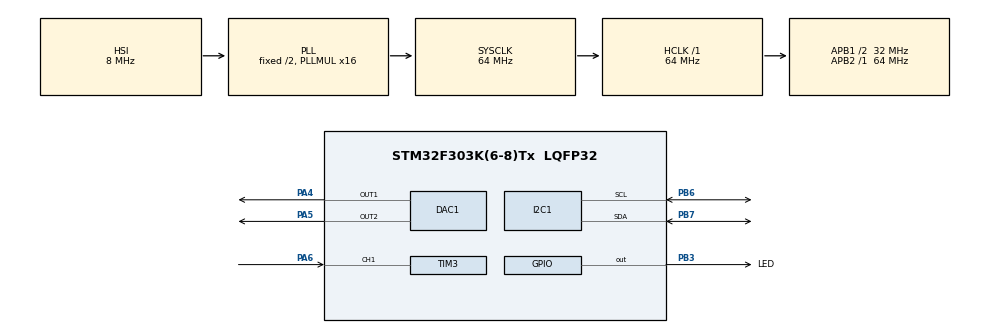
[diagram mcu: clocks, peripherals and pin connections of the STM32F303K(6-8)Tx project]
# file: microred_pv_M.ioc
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I2C1.I2C_Fall_Time=0
I2C1.I2C_Rise_Time=0
I2C1.OwnAddress=16
Mcu.Family=STM32F3
Mcu.Name=STM32F303K(6-8)Tx
Mcu.Package=LQFP32
NVIC.I2C1_ER_IRQn=true\:2\:0\:true\:false\:true\:true\:true\:true
NVIC.I2C1_EV_IRQn=true\:2\:0\:true\:false\:true\:true\:true\:true
NVIC.PriorityGroup=NVIC_PRIORITYGROUP_4
NVIC.TIM6_DAC1_IRQn=true\:1\:0\:true\:false\:true\:true\:true\:true
PA13.Mode=Serial_Wire
PA13.Signal=SYS_JTMS-SWDIO
PA14.Mode=Serial_Wire
PA14.Signal=SYS_JTCK-SWCLK
PA4.Signal=COMP_DAC11_group
PA5.Signal=COMP_DAC12_group
PA6.Signal=S_TIM3_CH1
PB3.GPIO_Label=LED
PB3.Signal=GPIO_Output
PB6.Mode=I2C
PB6.Signal=I2C1_SCL
PB7.Mode=I2C
PB7.Signal=I2C1_SDA
ProjectManager.HeapSize=0x200
ProjectManager.StackSize=0x400
ProjectManager.TargetToolchain=CMake
RCC.AHBFreq_Value=64000000
RCC.APB1CLKDivider=RCC_HCLK_DIV2
RCC.APB1Freq_Value=32000000
RCC.APB1TimFreq_Value=64000000
RCC.APB2Freq_Value=64000000
RCC.APB2TimFreq_Value=64000000
RCC.CortexFreq_Value=64000000
RCC.HCLKFreq_Value=64000000
RCC.HSE_VALUE=8000000
RCC.HSI_VALUE=8000000
RCC.PLLMUL=RCC_PLL_MUL16
RCC.SYSCLKFreq_VALUE=64000000
RCC.SYSCLKSourceVirtual=RCC_SYSCLKSOURCE_PLLCLK
SH.COMP_DAC11_group.0=DAC1_OUT1,DAC_OUT1
SH.COMP_DAC12_group.0=DAC1_OUT2,DAC_OUT2
SH.S_TIM3_CH1.0=TIM3_CH1,PWM_Input_1
TIM6.Period=99
TIM6.Prescaler=63
VP_TIM3_VS_ClockSourceINT.Mode=Internal
VP_TIM6_VS_ClockSourceINT.Mode=Enable_Timer
board=custom

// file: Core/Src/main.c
/* USER CODE BEGIN Header */
/**
  ******************************************************************************
  * @file           : main.c
  * @brief          : Main program body
  ******************************************************************************
  * @attention
  *
  * Copyright (c) 2026 STMicroelectronics.
  * All rights reserved.
  *
  * This software is licensed under terms that can be found in the LICENSE file
  * in the root directory of this software component.
  * If no LICENSE file comes with this software, it is provided AS-IS.
  *
  ******************************************************************************
  */
/* USER CODE END Header */
#include "main.h"

/* USER CODE BEGIN Includes */
#include "app_sub.h"
/* USER CODE END Includes */

DAC_HandleTypeDef hdac1;

I2C_HandleTypeDef hi2c1;

TIM_HandleTypeDef htim3;
TIM_HandleTypeDef htim6;

void SystemClock_Config(void);
static void MX_GPIO_Init(void);
static void MX_I2C1_Init(void);
static void MX_DAC1_Init(void);
static void MX_TIM3_Init(void);
static void MX_TIM6_Init(void);

int main(void)
{

  /* MCU Configuration--------------------------------------------------------*/

  /* Reset of all peripherals, Initializes the Flash interface and the Systick. */
  HAL_Init();

  /* Configure the system clock */
  SystemClock_Config();

  /* Initialize all configured peripherals */
  MX_GPIO_Init();
  MX_I2C1_Init();
  MX_DAC1_Init();
  MX_TIM3_Init();
  MX_TIM6_Init();
  /* USER CODE BEGIN 2 */
  sub_init();
  /* USER CODE END 2 */

  /* Infinite loop */
  while (1)
  {

    /* USER CODE BEGIN 3 */
    sub_loop();

  /* USER CODE END 3 */
}
}
void SystemClock_Config(void)
{
  RCC_OscInitTypeDef RCC_OscInitStruct = {0};
  RCC_ClkInitTypeDef RCC_ClkInitStruct = {0};
  RCC_PeriphCLKInitTypeDef PeriphClkInit = {0};

  /** Initializes the RCC Oscillators according to the specified parameters
  * in the RCC_OscInitTypeDef structure.
  */
  RCC_OscInitStruct.OscillatorType = RCC_OSCILLATORTYPE_HSI;
  RCC_OscInitStruct.HSIState = RCC_HSI_ON;
  RCC_OscInitStruct.HSICalibrationValue = RCC_HSICALIBRATION_DEFAULT;
  RCC_OscInitStruct.PLL.PLLState = RCC_PLL_ON;
  RCC_OscInitStruct.PLL.PLLSource = RCC_PLLSOURCE_HSI;
  RCC_OscInitStruct.PLL.PLLMUL = RCC_PLL_MUL16;
  if (HAL_RCC_OscConfig(&RCC_OscInitStruct) != HAL_OK)
  {
    Error_Handler();
  }

  /** Initializes the CPU, AHB and APB buses clocks
  */
  RCC_ClkInitStruct.ClockType = RCC_CLOCKTYPE_HCLK|RCC_CLOCKTYPE_SYSCLK
                              |RCC_CLOCKTYPE_PCLK1|RCC_CLOCKTYPE_PCLK2;
  RCC_ClkInitStruct.SYSCLKSource = RCC_SYSCLKSOURCE_PLLCLK;
  RCC_ClkInitStruct.AHBCLKDivider = RCC_SYSCLK_DIV1;
  RCC_ClkInitStruct.APB1CLKDivider = RCC_HCLK_DIV2;
  RCC_ClkInitStruct.APB2CLKDivider = RCC_HCLK_DIV1;

  if (HAL_RCC_ClockConfig(&RCC_ClkInitStruct, FLASH_LATENCY_2) != HAL_OK)
  {
    Error_Handler();
  }
  PeriphClkInit.PeriphClockSelection = RCC_PERIPHCLK_I2C1;
  PeriphClkInit.I2c1ClockSelection = RCC_I2C1CLKSOURCE_HSI;
  if (HAL_RCCEx_PeriphCLKConfig(&PeriphClkInit) != HAL_OK)
  {
    Error_Handler();
  }
}

static void MX_DAC1_Init(void)
{

  DAC_ChannelConfTypeDef sConfig = {0};

  /** DAC Initialization
  */
  hdac1.Instance = DAC1;
  if (HAL_DAC_Init(&hdac1) != HAL_OK)
  {
    Error_Handler();
  }

  /** DAC channel OUT1 config
  */
  sConfig.DAC_Trigger = DAC_TRIGGER_NONE;
  sConfig.DAC_OutputBuffer = DAC_OUTPUTBUFFER_ENABLE;
  if (HAL_DAC_ConfigChannel(&hdac1, &sConfig, DAC_CHANNEL_1) != HAL_OK)
  {
    Error_Handler();
  }

  /** DAC channel OUT2 config
  */
  sConfig.DAC_OutputSwitch = DAC_OUTPUTSWITCH_ENABLE;
  if (HAL_DAC_ConfigChannel(&hdac1, &sConfig, DAC_CHANNEL_2) != HAL_OK)
  {
    Error_Handler();
  }

}

static void MX_I2C1_Init(void)
{

  hi2c1.Instance = I2C1;
  hi2c1.Init.Timing = 0x2000090E;
  hi2c1.Init.OwnAddress1 = 32;
  hi2c1.Init.AddressingMode = I2C_ADDRESSINGMODE_7BIT;
  hi2c1.Init.DualAddressMode = I2C_DUALADDRESS_DISABLE;
  hi2c1.Init.OwnAddress2 = 0;
  hi2c1.Init.OwnAddress2Masks = I2C_OA2_NOMASK;
  hi2c1.Init.GeneralCallMode = I2C_GENERALCALL_DISABLE;
  hi2c1.Init.NoStretchMode = I2C_NOSTRETCH_DISABLE;
  if (HAL_I2C_Init(&hi2c1) != HAL_OK)
  {
    Error_Handler();
  }

  /** Configure Analogue filter
  */
  if (HAL_I2CEx_ConfigAnalogFilter(&hi2c1, I2C_ANALOGFILTER_ENABLE) != HAL_OK)
  {
    Error_Handler();
  }

  /** Configure Digital filter
  */
  if (HAL_I2CEx_ConfigDigitalFilter(&hi2c1, 0) != HAL_OK)
  {
    Error_Handler();
  }

}

static void MX_TIM3_Init(void)
{

  TIM_ClockConfigTypeDef sClockSourceConfig = {0};
  TIM_SlaveConfigTypeDef sSlaveConfig = {0};
  TIM_IC_InitTypeDef sConfigIC = {0};
  TIM_MasterConfigTypeDef sMasterConfig = {0};

  htim3.Instance = TIM3;
  htim3.Init.Prescaler = 0;
  htim3.Init.CounterMode = TIM_COUNTERMODE_UP;
  htim3.Init.Period = 65535;
  htim3.Init.ClockDivision = TIM_CLOCKDIVISION_DIV1;
  htim3.Init.AutoReloadPreload = TIM_AUTORELOAD_PRELOAD_DISABLE;
  if (HAL_TIM_Base_Init(&htim3) != HAL_OK)
  {
    Error_Handler();
  }
  sClockSourceConfig.ClockSource = TIM_CLOCKSOURCE_INTERNAL;
  if (HAL_TIM_ConfigClockSource(&htim3, &sClockSourceConfig) != HAL_OK)
  {
    Error_Handler();
  }
  if (HAL_TIM_IC_Init(&htim3) != HAL_OK)
  {
    Error_Handler();
  }
  sSlaveConfig.SlaveMode = TIM_SLAVEMODE_RESET;
  sSlaveConfig.InputTrigger = TIM_TS_TI1FP1;
  sSlaveConfig.TriggerPolarity = TIM_INPUTCHANNELPOLARITY_RISING;
  sSlaveConfig.TriggerPrescaler = TIM_ICPSC_DIV1;
  sSlaveConfig.TriggerFilter = 0;
  if (HAL_TIM_SlaveConfigSynchro(&htim3, &sSlaveConfig) != HAL_OK)
  {
    Error_Handler();
  }
  sConfigIC.ICPolarity = TIM_INPUTCHANNELPOLARITY_RISING;
  sConfigIC.ICSelection = TIM_ICSELECTION_DIRECTTI;
  sConfigIC.ICPrescaler = TIM_ICPSC_DIV1;
  sConfigIC.ICFilter = 0;
  if (HAL_TIM_IC_ConfigChannel(&htim3, &sConfigIC, TIM_CHANNEL_1) != HAL_OK)
  {
    Error_Handler();
  }
  sConfigIC.ICPolarity = TIM_INPUTCHANNELPOLARITY_FALLING;
  sConfigIC.ICSelection = TIM_ICSELECTION_INDIRECTTI;
  if (HAL_TIM_IC_ConfigChannel(&htim3, &sConfigIC, TIM_CHANNEL_2) != HAL_OK)
  {
    Error_Handler();
  }
  sMasterConfig.MasterOutputTrigger = TIM_TRGO_RESET;
  sMasterConfig.MasterSlaveMode = TIM_MASTERSLAVEMODE_DISABLE;
  if (HAL_TIMEx_MasterConfigSynchronization(&htim3, &sMasterConfig) != HAL_OK)
  {
    Error_Handler();
  }

}

static void MX_TIM6_Init(void)
{

  TIM_MasterConfigTypeDef sMasterConfig = {0};

  htim6.Instance = TIM6;
  htim6.Init.Prescaler = 63;
  htim6.Init.CounterMode = TIM_COUNTERMODE_UP;
  htim6.Init.Period = 99;
  htim6.Init.AutoReloadPreload = TIM_AUTORELOAD_PRELOAD_DISABLE;
  if (HAL_TIM_Base_Init(&htim6) != HAL_OK)
  {
    Error_Handler();
  }
  sMasterConfig.MasterOutputTrigger = TIM_TRGO_RESET;
  sMasterConfig.MasterSlaveMode = TIM_MASTERSLAVEMODE_DISABLE;
  if (HAL_TIMEx_MasterConfigSynchronization(&htim6, &sMasterConfig) != HAL_OK)
  {
    Error_Handler();
  }

}

static void MX_GPIO_Init(void)
{
  GPIO_InitTypeDef GPIO_InitStruct = {0};

  /* GPIO Ports Clock Enable */
  __HAL_RCC_GPIOA_CLK_ENABLE();
  __HAL_RCC_GPIOB_CLK_ENABLE();

  /*Configure GPIO pin Output Level */
  HAL_GPIO_WritePin(LED_GPIO_Port, LED_Pin, GPIO_PIN_RESET);

  /*Configure GPIO pin : LED_Pin */
  GPIO_InitStruct.Pin = LED_Pin;
  GPIO_InitStruct.Mode = GPIO_MODE_OUTPUT_PP;
  GPIO_InitStruct.Pull = GPIO_NOPULL;
  GPIO_InitStruct.Speed = GPIO_SPEED_FREQ_LOW;
  HAL_GPIO_Init(LED_GPIO_Port, &GPIO_InitStruct);

}

void Error_Handler(void)
{
  __disable_irq();
  while (1)
  {
  }
}
